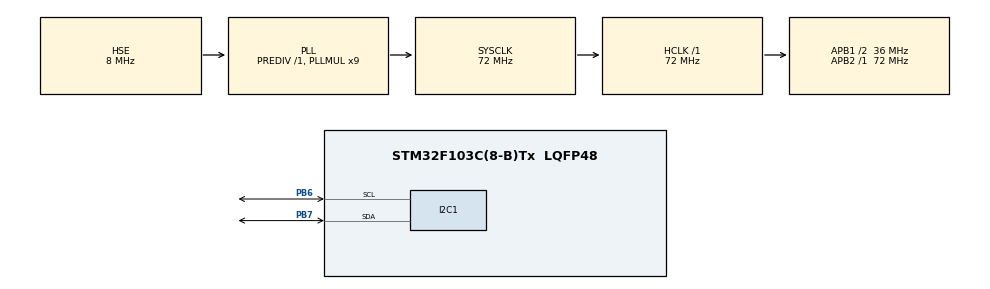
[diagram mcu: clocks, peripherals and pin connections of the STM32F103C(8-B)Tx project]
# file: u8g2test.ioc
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Mcu.Family=STM32F1
Mcu.Name=STM32F103C(8-B)Tx
Mcu.Package=LQFP48
NVIC.PriorityGroup=NVIC_PRIORITYGROUP_4
PA13.Mode=Serial_Wire
PA13.Signal=SYS_JTMS-SWDIO
PA14.Mode=Serial_Wire
PA14.Signal=SYS_JTCK-SWCLK
PB6.Mode=I2C
PB6.Signal=I2C1_SCL
PB7.Mode=I2C
PB7.Signal=I2C1_SDA
PD0-OSC_IN.Mode=HSE-External-Oscillator
PD0-OSC_IN.Signal=RCC_OSC_IN
PD1-OSC_OUT.Mode=HSE-External-Oscillator
PD1-OSC_OUT.Signal=RCC_OSC_OUT
ProjectManager.HeapSize=0x200
ProjectManager.StackSize=0x400
ProjectManager.TargetToolchain=STM32CubeIDE
RCC.AHBFreq_Value=72000000
RCC.APB1CLKDivider=RCC_HCLK_DIV2
RCC.APB1Freq_Value=36000000
RCC.APB1TimFreq_Value=72000000
RCC.APB2Freq_Value=72000000
RCC.APB2TimFreq_Value=72000000
RCC.HCLKFreq_Value=72000000
RCC.PLLMUL=RCC_PLL_MUL9
RCC.PLLSourceVirtual=RCC_PLLSOURCE_HSE
RCC.SYSCLKFreq_VALUE=72000000
RCC.SYSCLKSource=RCC_SYSCLKSOURCE_PLLCLK
RCC.USBFreq_Value=72000000
board=custom

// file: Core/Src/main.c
/* USER CODE BEGIN Header */
/**
 ******************************************************************************
 * @file           : main.c
 * @brief          : Main program body
 ******************************************************************************
 * @attention
 *
 * Copyright (c) 2026 STMicroelectronics.
 * All rights reserved.
 *
 * This software is licensed under terms that can be found in the LICENSE file
 * in the root directory of this software component.
 * If no LICENSE file comes with this software, it is provided AS-IS.
 *
 ******************************************************************************
 */
/* USER CODE END Header */
#include "main.h"

/* USER CODE BEGIN Includes */
#include "delay.h"
#include "u8g2.h"
#include "iic.h"
/* USER CODE END Includes */

I2C_HandleTypeDef hi2c1;

void SystemClock_Config(void);
static void MX_GPIO_Init(void);
static void MX_I2C1_Init(void);

/* USER CODE BEGIN 0 */
uint8_t u8x8_gpio_and_delay_stm32f1(u8x8_t *u8x8, uint8_t msg, uint8_t arg_int, void *arg_ptr)
{
    switch (msg)
    {
    case U8X8_MSG_GPIO_AND_DELAY_INIT: // called once during init phase of u8g2/u8x8

        // 打开对应的时钟
        __HAL_RCC_GPIOB_CLK_ENABLE();
        // 初始化SCL
        GPIO_InitTypeDef GPIO_Init_Struct = {};
        GPIO_Init_Struct.Mode = GPIO_MODE_OUTPUT_OD;
        GPIO_Init_Struct.Pull = GPIO_NOPULL;
        GPIO_Init_Struct.Pin = IIC_SCL_PIN;
        GPIO_Init_Struct.Speed = GPIO_SPEED_FREQ_HIGH;
        HAL_GPIO_Init(IIC_SCL_PORT, &GPIO_Init_Struct);

        // 初始化SDA
        GPIO_Init_Struct.Mode = GPIO_MODE_OUTPUT_OD;
        GPIO_Init_Struct.Pull = GPIO_NOPULL;
        GPIO_Init_Struct.Pin = IIC_SDA_PIN;
        GPIO_Init_Struct.Speed = GPIO_SPEED_FREQ_HIGH;
        HAL_GPIO_Init(IIC_SDA_PORT, &GPIO_Init_Struct);

        delay_init(72);       // 初始化delay
        break;                // can be used to setup pins
    case U8X8_MSG_DELAY_NANO: // delay arg_int * 1 nano second
        __NOP();
        break;
    case U8X8_MSG_DELAY_100NANO: // delay arg_int * 100 nano seconds
        __NOP();
        break;
    case U8X8_MSG_DELAY_10MICRO: // delay arg_int * 10 micro seconds
        delay_us(10 * arg_int);
        break;
    case U8X8_MSG_DELAY_MILLI: // delay arg_int * 1 milli second
        delay_ms(arg_int);
        break;
    case U8X8_MSG_DELAY_I2C: // arg_int is the I2C speed in 100KHz, e.g. 4 = 400 KHz
        if (arg_int == 1)
        {
            delay_us(5);
        }
        if (arg_int == 4)
        {
            delay_us(2);
        }
        break;                    // arg_int=1: delay by 5us, arg_int = 4: delay by 1.25us
    case U8X8_MSG_GPIO_I2C_CLOCK: // arg_int=0: Output low at I2C clock pin
        SCL_Write(arg_int);
        break;                   // arg_int=1: Input dir with pullup high for I2C clock pin
    case U8X8_MSG_GPIO_I2C_DATA: // arg_int=0: Output low at I2C data pin
        SDA_Write(arg_int);
        break; // arg_int=1: Input dir with pullup high for I2C data pin
    case U8X8_MSG_GPIO_MENU_SELECT:
        u8x8_SetGPIOResult(u8x8, /* get menu select pin state */ 0);
        break;
    case U8X8_MSG_GPIO_MENU_NEXT:
        u8x8_SetGPIOResult(u8x8, /* get menu next pin state */ 0);
        break;
    case U8X8_MSG_GPIO_MENU_PREV:
        u8x8_SetGPIOResult(u8x8, /* get menu prev pin state */ 0);
        break;
    case U8X8_MSG_GPIO_MENU_HOME:
        u8x8_SetGPIOResult(u8x8, /* get menu home pin state */ 0);
        break;
    default:
        u8x8_SetGPIOResult(u8x8, 1); // default return value
        break;
    }
    return 1;
}

void u8g2_init()
{
    u8g2_t u8g2;
    u8g2_Setup_ssd1306_i2c_128x64_noname_f(&u8g2, U8G2_R0, u8x8_byte_sw_i2c, u8x8_gpio_and_delay_stm32f1);
    u8g2_InitDisplay(&u8g2);     // send init sequence to the display, display is in sleep mode after this,
    u8g2_SetPowerSave(&u8g2, 0); // wake up display
                                 // 清除缓冲区
    u8g2_ClearBuffer(&u8g2);
    01u8g2_DrawBox(&u8g2, 10, 10, 10, 10);
}10
/* USER CODE END 0 */

int main(void)
{

    /* MCU Configuration--------------------------------------------------------*/

    /* Reset of all peripherals, Initializes the Flash interface and the Systick. */
    HAL_Init();

    /* Configure the system clock */
    SystemClock_Config();

    /* Initialize all configured peripherals */
    MX_GPIO_Init();
    MX_I2C1_Init();

    /* Infinite loop */
    while (1)
    {

    }
}

void SystemClock_Config(void)
{
    RCC_OscInitTypeDef RCC_OscInitStruct = {0};
    RCC_ClkInitTypeDef RCC_ClkInitStruct = {0};

    /** Initializes the RCC Oscillators according to the specified parameters
     * in the RCC_OscInitTypeDef structure.
     */
    RCC_OscInitStruct.OscillatorType = RCC_OSCILLATORTYPE_HSE;
    RCC_OscInitStruct.HSEState = RCC_HSE_ON;
    RCC_OscInitStruct.HSEPredivValue = RCC_HSE_PREDIV_DIV1;
    RCC_OscInitStruct.HSIState = RCC_HSI_ON;
    RCC_OscInitStruct.PLL.PLLState = RCC_PLL_ON;
    RCC_OscInitStruct.PLL.PLLSource = RCC_PLLSOURCE_HSE;
    RCC_OscInitStruct.PLL.PLLMUL = RCC_PLL_MUL9;
    if (HAL_RCC_OscConfig(&RCC_OscInitStruct) != HAL_OK)
    {
        Error_Handler();
    }

    /** Initializes the CPU, AHB and APB buses clocks
     */
    RCC_ClkInitStruct.ClockType = RCC_CLOCKTYPE_HCLK | RCC_CLOCKTYPE_SYSCLK | RCC_CLOCKTYPE_PCLK1 | RCC_CLOCKTYPE_PCLK2;
    RCC_ClkInitStruct.SYSCLKSource = RCC_SYSCLKSOURCE_PLLCLK;
    RCC_ClkInitStruct.AHBCLKDivider = RCC_SYSCLK_DIV1;
    RCC_ClkInitStruct.APB1CLKDivider = RCC_HCLK_DIV2;
    RCC_ClkInitStruct.APB2CLKDivider = RCC_HCLK_DIV1;

    if (HAL_RCC_ClockConfig(&RCC_ClkInitStruct, FLASH_LATENCY_2) != HAL_OK)
    {
        Error_Handler();
    }
}

static void MX_I2C1_Init(void)
{

    hi2c1.Instance = I2C1;
    hi2c1.Init.ClockSpeed = 100000;
    hi2c1.Init.DutyCycle = I2C_DUTYCYCLE_2;
    hi2c1.Init.OwnAddress1 = 0;
    hi2c1.Init.AddressingMode = I2C_ADDRESSINGMODE_7BIT;
    hi2c1.Init.DualAddressMode = I2C_DUALADDRESS_DISABLE;
    hi2c1.Init.OwnAddress2 = 0;
    hi2c1.Init.GeneralCallMode = I2C_GENERALCALL_DISABLE;
    hi2c1.Init.NoStretchMode = I2C_NOSTRETCH_DISABLE;
    if (HAL_I2C_Init(&hi2c1) != HAL_OK)
    {
        Error_Handler();
    }
}

static void MX_GPIO_Init(void)
{

    /* GPIO Ports Clock Enable */
    __HAL_RCC_GPIOD_CLK_ENABLE();
    __HAL_RCC_GPIOA_CLK_ENABLE();
    __HAL_RCC_GPIOB_CLK_ENABLE();

}

void Error_Handler(void)
{
    __disable_irq();
    while (1)
    {
    }
}
